# ESP32-P4 register map
Vendor: ESPRESSIF SYSTEMS (SHANGHAI) CO., LTD.; Series: ESP32 P-Series; File version: 3
CPU: RV32IMAFC r0p0, little endian, no MPU, FPU, 0 interrupt priority bits
Address unit: 32 bits
Registers are 32-bit, read-write, reset 0x0 unless marked. A register's access mark holds for its fields unless they carry their own. Offsets are from the block's base; [hi:lo] are bit positions.

## LP_INTR — Low-power Interrupt Controller
Base 0x5012C000
0x00 SW_INT_RAW — need_des
  [31] LP_SW_INT_RAW
0x04 SW_INT_ST ro — need_des
  [31] LP_SW_INT_ST
0x08 SW_INT_ENA — need_des
  [31] LP_SW_INT_ENA
0x0C SW_INT_CLR wo — need_des
  [31] LP_SW_INT_CLR
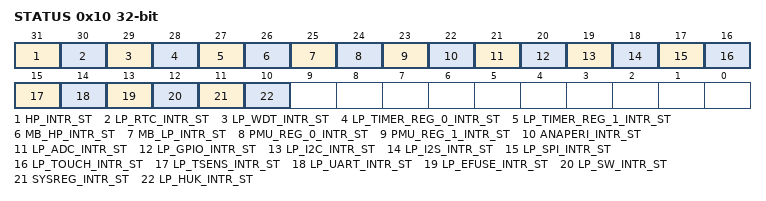
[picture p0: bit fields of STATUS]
0x10 STATUS ro — need_des
  [31] HP_INTR_ST — need_des
  [30] LP_RTC_INTR_ST — need_des
  [29] LP_WDT_INTR_ST — need_des
  [28] LP_TIMER_REG_0_INTR_ST — need_des
  [27] LP_TIMER_REG_1_INTR_ST — need_des
  [26] MB_HP_INTR_ST — need_des
  [25] MB_LP_INTR_ST — need_des
  [24] PMU_REG_0_INTR_ST — need_des
  [23] PMU_REG_1_INTR_ST — need_des
  [22] ANAPERI_INTR_ST — need_des
  [21] LP_ADC_INTR_ST — need_des
  [20] LP_GPIO_INTR_ST — need_des
  [19] LP_I2C_INTR_ST — need_des
  [18] LP_I2S_INTR_ST — need_des
  [17] LP_SPI_INTR_ST — need_des
  [16] LP_TOUCH_INTR_ST — need_des
  [15] LP_TSENS_INTR_ST — need_des
  [14] LP_UART_INTR_ST — need_des
  [13] LP_EFUSE_INTR_ST — need_des
  [12] LP_SW_INTR_ST — need_des
  [11] SYSREG_INTR_ST — need_des
  [10] LP_HUK_INTR_ST — need_des
0x3FC DATE — need_des
  [31] CLK_EN

## LP_PERI — LP_PERI Peripheral
Base 0x50120000
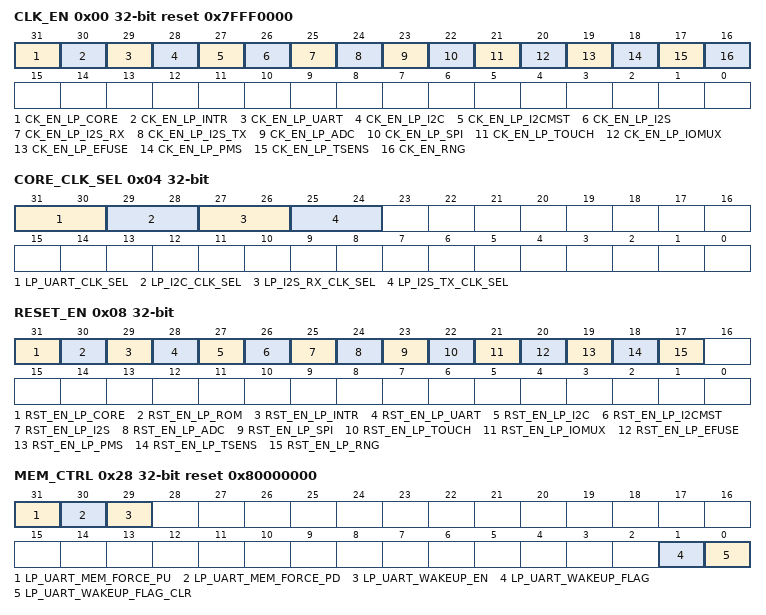
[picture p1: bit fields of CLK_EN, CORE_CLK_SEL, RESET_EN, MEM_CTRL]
0x00 CLK_EN reset 0x7FFF0000 — need_des
  [31] CK_EN_LP_CORE — write 1 to force on lp_core clk
  [30] CK_EN_LP_INTR — need_des
  [29] CK_EN_LP_UART — need_des
  [28] CK_EN_LP_I2C — need_des
  [27] CK_EN_LP_I2CMST — need_des
  [26] CK_EN_LP_I2S — need_des
  [25] CK_EN_LP_I2S_RX — need_des
  [24] CK_EN_LP_I2S_TX — need_des
  [23] CK_EN_LP_ADC — need_des
  [22] CK_EN_LP_SPI — need_des
  [21] CK_EN_LP_TOUCH — need_des
  [20] CK_EN_LP_IOMUX — need_des
  [19] CK_EN_LP_EFUSE — need_des
  [18] CK_EN_LP_PMS — need_des
  [17] CK_EN_LP_TSENS — need_des
  [16] CK_EN_RNG — need_des
0x04 CORE_CLK_SEL — need_des
  [31:30] LP_UART_CLK_SEL — need_des
  [29:28] LP_I2C_CLK_SEL — need_des
  [27:26] LP_I2S_RX_CLK_SEL — need_des
  [25:24] LP_I2S_TX_CLK_SEL — need_des
0x08 RESET_EN access per field — need_des
  [31] RST_EN_LP_CORE wo — need_des
  [30] RST_EN_LP_ROM rw — need_des
  [29] RST_EN_LP_INTR rw — need_des
  [28] RST_EN_LP_UART rw — need_des
  [27] RST_EN_LP_I2C rw — need_des
  [26] RST_EN_LP_I2CMST rw — need_des
  [25] RST_EN_LP_I2S rw — need_des
  [24] RST_EN_LP_ADC rw — need_des
  [23] RST_EN_LP_SPI rw — need_des
  [22] RST_EN_LP_TOUCH rw — need_des
  [21] RST_EN_LP_IOMUX rw — need_des
  [20] RST_EN_LP_EFUSE rw — need_des
  [19] RST_EN_LP_PMS rw — need_des
  [18] RST_EN_LP_TSENS rw — need_des
  [17] RST_EN_LP_RNG rw — need_des
0x0C CPU reset 0x80000000 — need_des
  [31] LPCORE_DBGM_UNAVAILABLE
0x28 MEM_CTRL access per field reset 0x80000000 — need_des
  [31] LP_UART_MEM_FORCE_PU rw — need_des
  [30] LP_UART_MEM_FORCE_PD rw — need_des
  [29] LP_UART_WAKEUP_EN rw — need_des
  [1] LP_UART_WAKEUP_FLAG rw — need_des
  [0] LP_UART_WAKEUP_FLAG_CLR wo — need_des
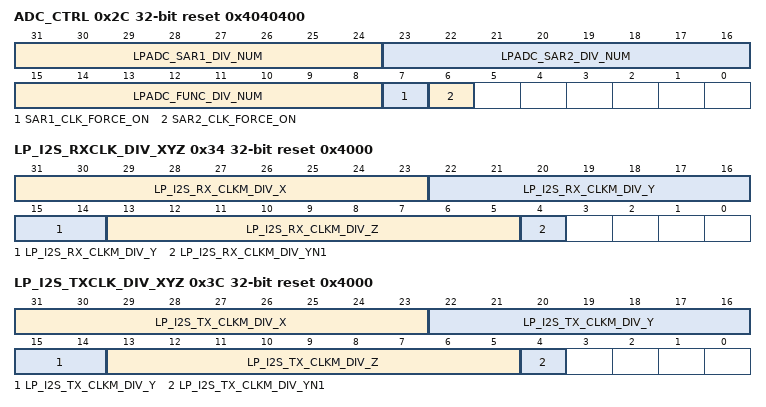
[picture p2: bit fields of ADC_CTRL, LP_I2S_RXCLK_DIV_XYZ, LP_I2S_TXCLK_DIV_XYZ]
0x2C ADC_CTRL reset 0x4040400 — need_des
  [31:24] LPADC_SAR1_DIV_NUM — need_des
  [23:16] LPADC_SAR2_DIV_NUM — need_des
  [15:8] LPADC_FUNC_DIV_NUM — need_des
  [7] SAR1_CLK_FORCE_ON — need_des
  [6] SAR2_CLK_FORCE_ON — need_des
0x30 LP_I2S_RXCLK_DIV_NUM reset 0x2000000 — need_des
  [31:24] LP_I2S_RX_CLKM_DIV_NUM
0x34 LP_I2S_RXCLK_DIV_XYZ reset 0x4000 — need_des
  [31:23] LP_I2S_RX_CLKM_DIV_X — need_des
  [22:14] LP_I2S_RX_CLKM_DIV_Y — need_des
  [13:5] LP_I2S_RX_CLKM_DIV_Z — need_des
  [4] LP_I2S_RX_CLKM_DIV_YN1 — need_des
0x38 LP_I2S_TXCLK_DIV_NUM reset 0x2000000 — need_des
  [31:24] LP_I2S_TX_CLKM_DIV_NUM
0x3C LP_I2S_TXCLK_DIV_XYZ reset 0x4000 — need_des
  [31:23] LP_I2S_TX_CLKM_DIV_X — need_des
  [22:14] LP_I2S_TX_CLKM_DIV_Y — need_des
  [13:5] LP_I2S_TX_CLKM_DIV_Z — need_des
  [4] LP_I2S_TX_CLKM_DIV_YN1 — need_des
0x3FC DATE — need_des
  [31] CLK_EN
